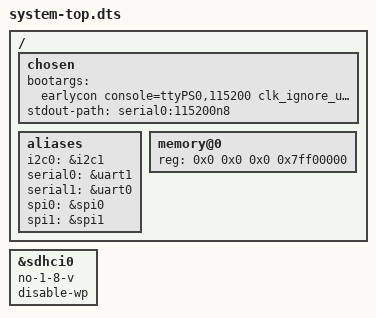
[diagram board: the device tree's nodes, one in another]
/*
 * CAUTION: This file is automatically generated by Xilinx.
 * Version: XSCT 2024.2
 * Today is: Mon Jan  6 02:20:17 2025
 */


/dts-v1/;
#include "zynqmp.dtsi"
#include "zynqmp-clk-ccf.dtsi"
#include "pcw.dtsi"
/ {
	chosen {
		bootargs = "earlycon console=ttyPS0,115200 clk_ignore_unused root=/dev/mmcblk0p2 rw rootwait cma=512M rfkill.default_state=1";
		stdout-path = "serial0:115200n8";
	};
	aliases {
		i2c0 = &i2c1;
		serial0 = &uart1;
		serial1 = &uart0;
		spi0 = &spi0;
		spi1 = &spi1;
	};
	memory@0 {
		device_type = "memory";
		reg = <0x0 0x0 0x0 0x7ff00000>;
	};
};

/* SD0 only supports 3.3V, no level shifter */
&sdhci0 {
	no-1-8-v;
	disable-wp;
};
